AUTOSAR XML (schema 00046)
standard types defined: uint8
package /DataTypes/ApplicationDataTypes
  app type AdtName1: category=VALUE
package /DataTypes/ImplementationDataTypes
  impl type IdtName1: category=VALUE, base-type=uint8
package /SoftwareTypes/ComponentTypes
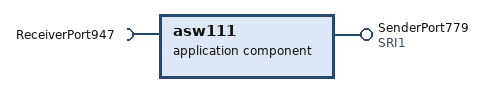
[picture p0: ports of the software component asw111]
  application sw component type asw111
    provide port SenderPort779: provided-interface=SRI1
    require port ReceiverPort947
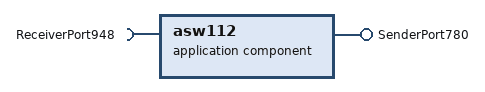
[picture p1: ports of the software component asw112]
  application sw component type asw112
    provide port SenderPort780
    require port ReceiverPort948
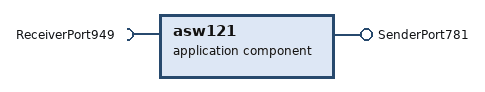
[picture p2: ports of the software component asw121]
  application sw component type asw121
    provide port SenderPort781
    require port ReceiverPort949
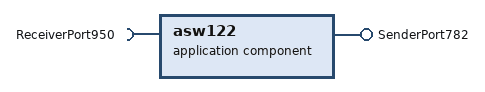
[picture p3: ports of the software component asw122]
  application sw component type asw122
    provide port SenderPort782
    require port ReceiverPort950
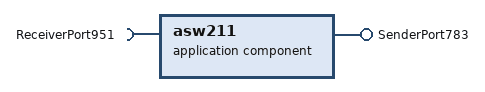
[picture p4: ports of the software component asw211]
  application sw component type asw211
    provide port SenderPort783
    require port ReceiverPort951
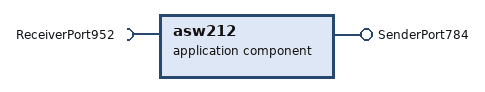
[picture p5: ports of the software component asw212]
  application sw component type asw212
    provide port SenderPort784
    require port ReceiverPort952
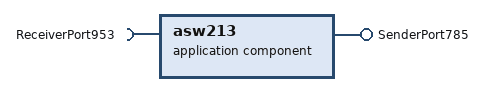
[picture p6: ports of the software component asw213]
  application sw component type asw213
    provide port SenderPort785
    require port ReceiverPort953
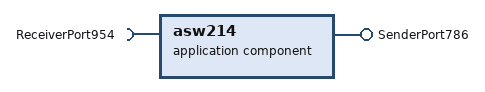
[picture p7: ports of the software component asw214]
  application sw component type asw214
    provide port SenderPort786
    require port ReceiverPort954
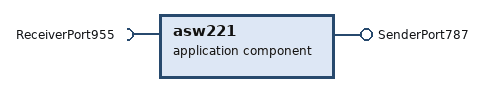
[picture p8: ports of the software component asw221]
  application sw component type asw221
    provide port SenderPort787
    require port ReceiverPort955
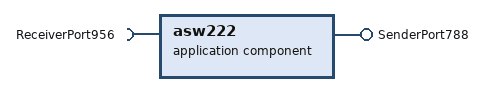
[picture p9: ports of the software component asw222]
  application sw component type asw222
    provide port SenderPort788
    require port ReceiverPort956
  composition sw component type c1
    component c11: type=c11
    component c12: type=c12
  composition sw component type c11
    component asw111: type=asw111
    component asw112: type=asw112
    component asw211: type=asw211
  composition sw component type c12
    component asw121: type=asw121
    component asw122: type=asw122
  composition sw component type c2
    component c21: type=c21
    component c22: type=c22
  composition sw component type c21
    4 x component:
      asw{211..214}: type=asw{211..214}
  composition sw component type c22
    component asw221: type=asw221
    component asw222: type=asw222
  composition sw component type r1
    component c1: type=c1
    component c2: type=c2
package /SoftwareTypes/Interfaces
  sender receiver interface SRI1
    data DE1: type=IdtName1
package /System
  system HEV
    system mapping Mappings117
      sw-mappings:
        swc to ecu mapping SwHwMapping190608: component=r1.c1.c11.asw111, ecu-instance=ecu1aliasname
    root-software-compositions:
      root sw composition prototype r1: software-composition=r1  # r1longname
package /Topology/HardwareComponents
  ecu instance ecu1aliasname: sleep-mode-supported=false, wake-up-over-bus-supported=false  # ecu1longname
